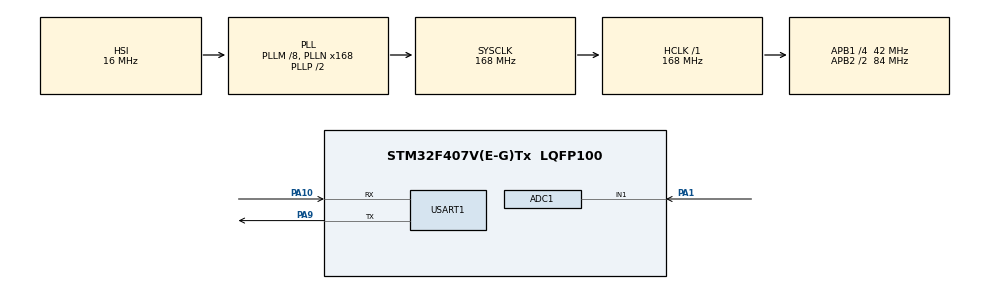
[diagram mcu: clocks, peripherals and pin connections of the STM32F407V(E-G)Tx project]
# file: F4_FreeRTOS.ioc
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ADC1.Channel-0\#ChannelRegularConversion=ADC_CHANNEL_1
ADC1.NbrOfConversionFlag=1
ADC1.Rank-0\#ChannelRegularConversion=1
ADC1.SamplingTime-0\#ChannelRegularConversion=ADC_SAMPLETIME_3CYCLES
ADC1.master=1
FREERTOS.Tasks01=defaultTask,0,128,StartDefaultTask,Default,NULL,Dynamic,NULL,NULL
Mcu.Family=STM32F4
Mcu.Name=STM32F407V(E-G)Tx
Mcu.Package=LQFP100
NVIC.PriorityGroup=NVIC_PRIORITYGROUP_4
NVIC.TIM8_TRG_COM_TIM14_IRQn=true\:15\:0\:false\:false\:true\:false\:false\:true\:true
NVIC.TimeBase=TIM8_TRG_COM_TIM14_IRQn
NVIC.TimeBaseIP=TIM14
PA1.Signal=ADCx_IN1
PA10.Mode=Asynchronous
PA10.Signal=USART1_RX
PA13.Mode=Serial_Wire
PA13.Signal=SYS_JTMS-SWDIO
PA14.Mode=Serial_Wire
PA14.Signal=SYS_JTCK-SWCLK
PA9.Mode=Asynchronous
PA9.Signal=USART1_TX
PH0-OSC_IN.Mode=HSE-External-Oscillator
PH0-OSC_IN.Signal=RCC_OSC_IN
PH1-OSC_OUT.Mode=HSE-External-Oscillator
PH1-OSC_OUT.Signal=RCC_OSC_OUT
ProjectManager.HeapSize=0x200
ProjectManager.StackSize=0x400
ProjectManager.TargetToolchain=MDK-ARM V5.32
RCC.48MHZClocksFreq_Value=84000000
RCC.AHBFreq_Value=168000000
RCC.APB1CLKDivider=RCC_HCLK_DIV4
RCC.APB1Freq_Value=42000000
RCC.APB1TimFreq_Value=84000000
RCC.APB2CLKDivider=RCC_HCLK_DIV2
RCC.APB2Freq_Value=84000000
RCC.APB2TimFreq_Value=168000000
RCC.CortexFreq_Value=168000000
RCC.HCLKFreq_Value=168000000
RCC.HSE_VALUE=25000000
RCC.HSI_VALUE=16000000
RCC.LSE_VALUE=32768
RCC.PLLM=8
RCC.PLLN=168
RCC.SYSCLKFreq_VALUE=168000000
RCC.SYSCLKSource=RCC_SYSCLKSOURCE_PLLCLK
RCC.VCOOutputFreq_Value=336000000
SH.ADCx_IN1.0=ADC1_IN1,IN1
USART1.VirtualMode=VM_ASYNC
VP_FREERTOS_VS_CMSIS_V1.Mode=CMSIS_V1
VP_SYS_VS_tim14.Mode=TIM14
board=custom

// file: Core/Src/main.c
/* USER CODE BEGIN Header */
/**
  ******************************************************************************
  * @file           : main.c
  * @brief          : Main program body
  ******************************************************************************
  * @attention
  *
  * Copyright (c) 2025 STMicroelectronics.
  * All rights reserved.
  *
  * This software is licensed under terms that can be found in the LICENSE file
  * in the root directory of this software component.
  * If no LICENSE file comes with this software, it is provided AS-IS.
  *
  ******************************************************************************
  */
/* USER CODE END Header */
#include "main.h"
#include "cmsis_os.h"
#include "adc.h"
#include "usart.h"
#include "gpio.h"

/* USER CODE BEGIN Includes */

#include "ADC_void.h"
#include "uart_void.h"
/* USER CODE END Includes */

void SystemClock_Config(void);
void MX_FREERTOS_Init(void);

int main(void)
{

  /* MCU Configuration--------------------------------------------------------*/

  /* Reset of all peripherals, Initializes the Flash interface and the Systick. */
  HAL_Init();

  /* Configure the system clock */
  SystemClock_Config();

  /* Initialize all configured peripherals */
  MX_GPIO_Init();
  MX_ADC1_Init();
  MX_USART1_UART_Init();

  /* Call init function for freertos objects (in cmsis_os2.c) */
  MX_FREERTOS_Init();

  /* Start scheduler */
  osKernelStart();

  /* We should never get here as control is now taken by the scheduler */

  /* Infinite loop */
  while (1)
  {

  }
}

void SystemClock_Config(void)
{
  RCC_OscInitTypeDef RCC_OscInitStruct = {0};
  RCC_ClkInitTypeDef RCC_ClkInitStruct = {0};

  /** Configure the main internal regulator output voltage
  */
  __HAL_RCC_PWR_CLK_ENABLE();
  __HAL_PWR_VOLTAGESCALING_CONFIG(PWR_REGULATOR_VOLTAGE_SCALE1);

  /** Initializes the RCC Oscillators according to the specified parameters
  * in the RCC_OscInitTypeDef structure.
  */
  RCC_OscInitStruct.OscillatorType = RCC_OSCILLATORTYPE_HSI;
  RCC_OscInitStruct.HSIState = RCC_HSI_ON;
  RCC_OscInitStruct.HSICalibrationValue = RCC_HSICALIBRATION_DEFAULT;
  RCC_OscInitStruct.PLL.PLLState = RCC_PLL_ON;
  RCC_OscInitStruct.PLL.PLLSource = RCC_PLLSOURCE_HSI;
  RCC_OscInitStruct.PLL.PLLM = 8;
  RCC_OscInitStruct.PLL.PLLN = 168;
  RCC_OscInitStruct.PLL.PLLP = RCC_PLLP_DIV2;
  RCC_OscInitStruct.PLL.PLLQ = 4;
  if (HAL_RCC_OscConfig(&RCC_OscInitStruct) != HAL_OK)
  {
    Error_Handler();
  }

  /** Initializes the CPU, AHB and APB buses clocks
  */
  RCC_ClkInitStruct.ClockType = RCC_CLOCKTYPE_HCLK|RCC_CLOCKTYPE_SYSCLK
                              |RCC_CLOCKTYPE_PCLK1|RCC_CLOCKTYPE_PCLK2;
  RCC_ClkInitStruct.SYSCLKSource = RCC_SYSCLKSOURCE_PLLCLK;
  RCC_ClkInitStruct.AHBCLKDivider = RCC_SYSCLK_DIV1;
  RCC_ClkInitStruct.APB1CLKDivider = RCC_HCLK_DIV4;
  RCC_ClkInitStruct.APB2CLKDivider = RCC_HCLK_DIV2;

  if (HAL_RCC_ClockConfig(&RCC_ClkInitStruct, FLASH_LATENCY_5) != HAL_OK)
  {
    Error_Handler();
  }
}

void HAL_TIM_PeriodElapsedCallback(TIM_HandleTypeDef *htim)
{
  if (htim->Instance == TIM14)
  {
    HAL_IncTick();
  }
}

void Error_Handler(void)
{
  __disable_irq();
  while (1)
  {
  }
}

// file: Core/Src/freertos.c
/* USER CODE BEGIN Header */
/**
  ******************************************************************************
  * File Name          : freertos.c
  * Description        : Code for freertos applications
  ******************************************************************************
  * @attention
  *
  * Copyright (c) 2025 STMicroelectronics.
  * All rights reserved.
  *
  * This software is licensed under terms that can be found in the LICENSE file
  * in the root directory of this software component.
  * If no LICENSE file comes with this software, it is provided AS-IS.
  *
  ******************************************************************************
  */
/* USER CODE END Header */

#include "FreeRTOS.h"
#include "task.h"
#include "main.h"
#include "cmsis_os.h"

/* USER CODE BEGIN Includes */
#include "ADC_void.h"
#include "uart_void.h"
#include "main.h"
#include "usart.h"
/* USER CODE END Includes */

osThreadId defaultTaskHandle;

/* USER CODE BEGIN FunctionPrototypes */

/* Add prototype for ADC_GetValue if not already included by headers */

/* USER CODE END FunctionPrototypes */

void StartDefaultTask(void const * argument);

void MX_FREERTOS_Init(void); /* (MISRA C 2004 rule 8.1) */

/* GetIdleTaskMemory prototype (linked to static allocation support) */
void vApplicationGetIdleTaskMemory( StaticTask_t **ppxIdleTaskTCBBuffer, StackType_t **ppxIdleTaskStackBuffer, uint32_t *pulIdleTaskStackSize );

/* USER CODE BEGIN GET_IDLE_TASK_MEMORY */
static StaticTask_t xIdleTaskTCBBuffer;
static StackType_t xIdleStack[configMINIMAL_STACK_SIZE];

void vApplicationGetIdleTaskMemory( StaticTask_t **ppxIdleTaskTCBBuffer, StackType_t **ppxIdleTaskStackBuffer, uint32_t *pulIdleTaskStackSize )
{
  *ppxIdleTaskTCBBuffer = &xIdleTaskTCBBuffer;
  *ppxIdleTaskStackBuffer = &xIdleStack[0];
  *pulIdleTaskStackSize = configMINIMAL_STACK_SIZE;
  /* place for user code */
}
/* USER CODE END GET_IDLE_TASK_MEMORY */

void MX_FREERTOS_Init(void) {

  /* Create the thread(s) */
  /* definition and creation of defaultTask */
  osThreadDef(defaultTask, StartDefaultTask, osPriorityNormal, 0, 128);
  defaultTaskHandle = osThreadCreate(osThread(defaultTask), NULL);

}

/* USER CODE BEGIN Header_StartDefaultTask */
/**
  * @brief  Function implementing the defaultTask thread.
  * @param  argument: Not used
  * @retval None
  */
 uint32_t adc_value = 0;
/* USER CODE END Header_StartDefaultTask */
void StartDefaultTask(void const * argument)
{
  /* USER CODE BEGIN StartDefaultTask */
  /* Infinite loop */
  for(;;)
  {
    ADC_Start(&hadc1);
    ADC_getvalue(&hadc1, &adc_value);
    int8_t adc_value_int8 = (int8_t)adc_value;
    HAL_UART_Transmit(&huart1, (uint8_t *)&adc_value_int8, sizeof(adc_value_int8), HAL_MAX_DELAY);
    vTaskDelay(1000);
  }
  /* USER CODE END StartDefaultTask */
}
